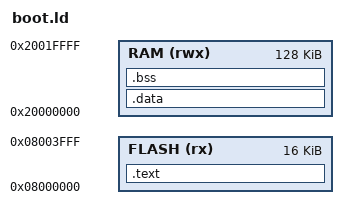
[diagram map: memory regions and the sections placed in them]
MEMORY
{
   FLASH (rx) : ORIGIN = 0x08000000, LENGTH = 0x00004000
    RAM (rwx) : ORIGIN = 0x20000000, LENGTH = 128K
}

SECTIONS
{
    .text :
    {
        _start_text = .;
        KEEP(*(.isr_vector))
        . = 0x400;
        KEEP(*(.text*))
        *(.rodata*)
        . = ALIGN(4);
        _end_text = .;
    } > FLASH

    _stored_data = .;

    .data : AT (_stored_data)
    {
        _start_data = .;
        KEEP(*(.data*))
        . = ALIGN(4);
        _end_data = .;
        . = ALIGN(0x1000);
    } > RAM

    .bss (NOLOAD) : 
    {
        _start_bss = .;
        *(.bss*)
        *(COMMON)
        . = ALIGN(4);
        _end_bss = .;
        _end = .;
    } > RAM
    . = ALIGN(4);
}

END_STACK = ORIGIN(RAM) + LENGTH(RAM);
